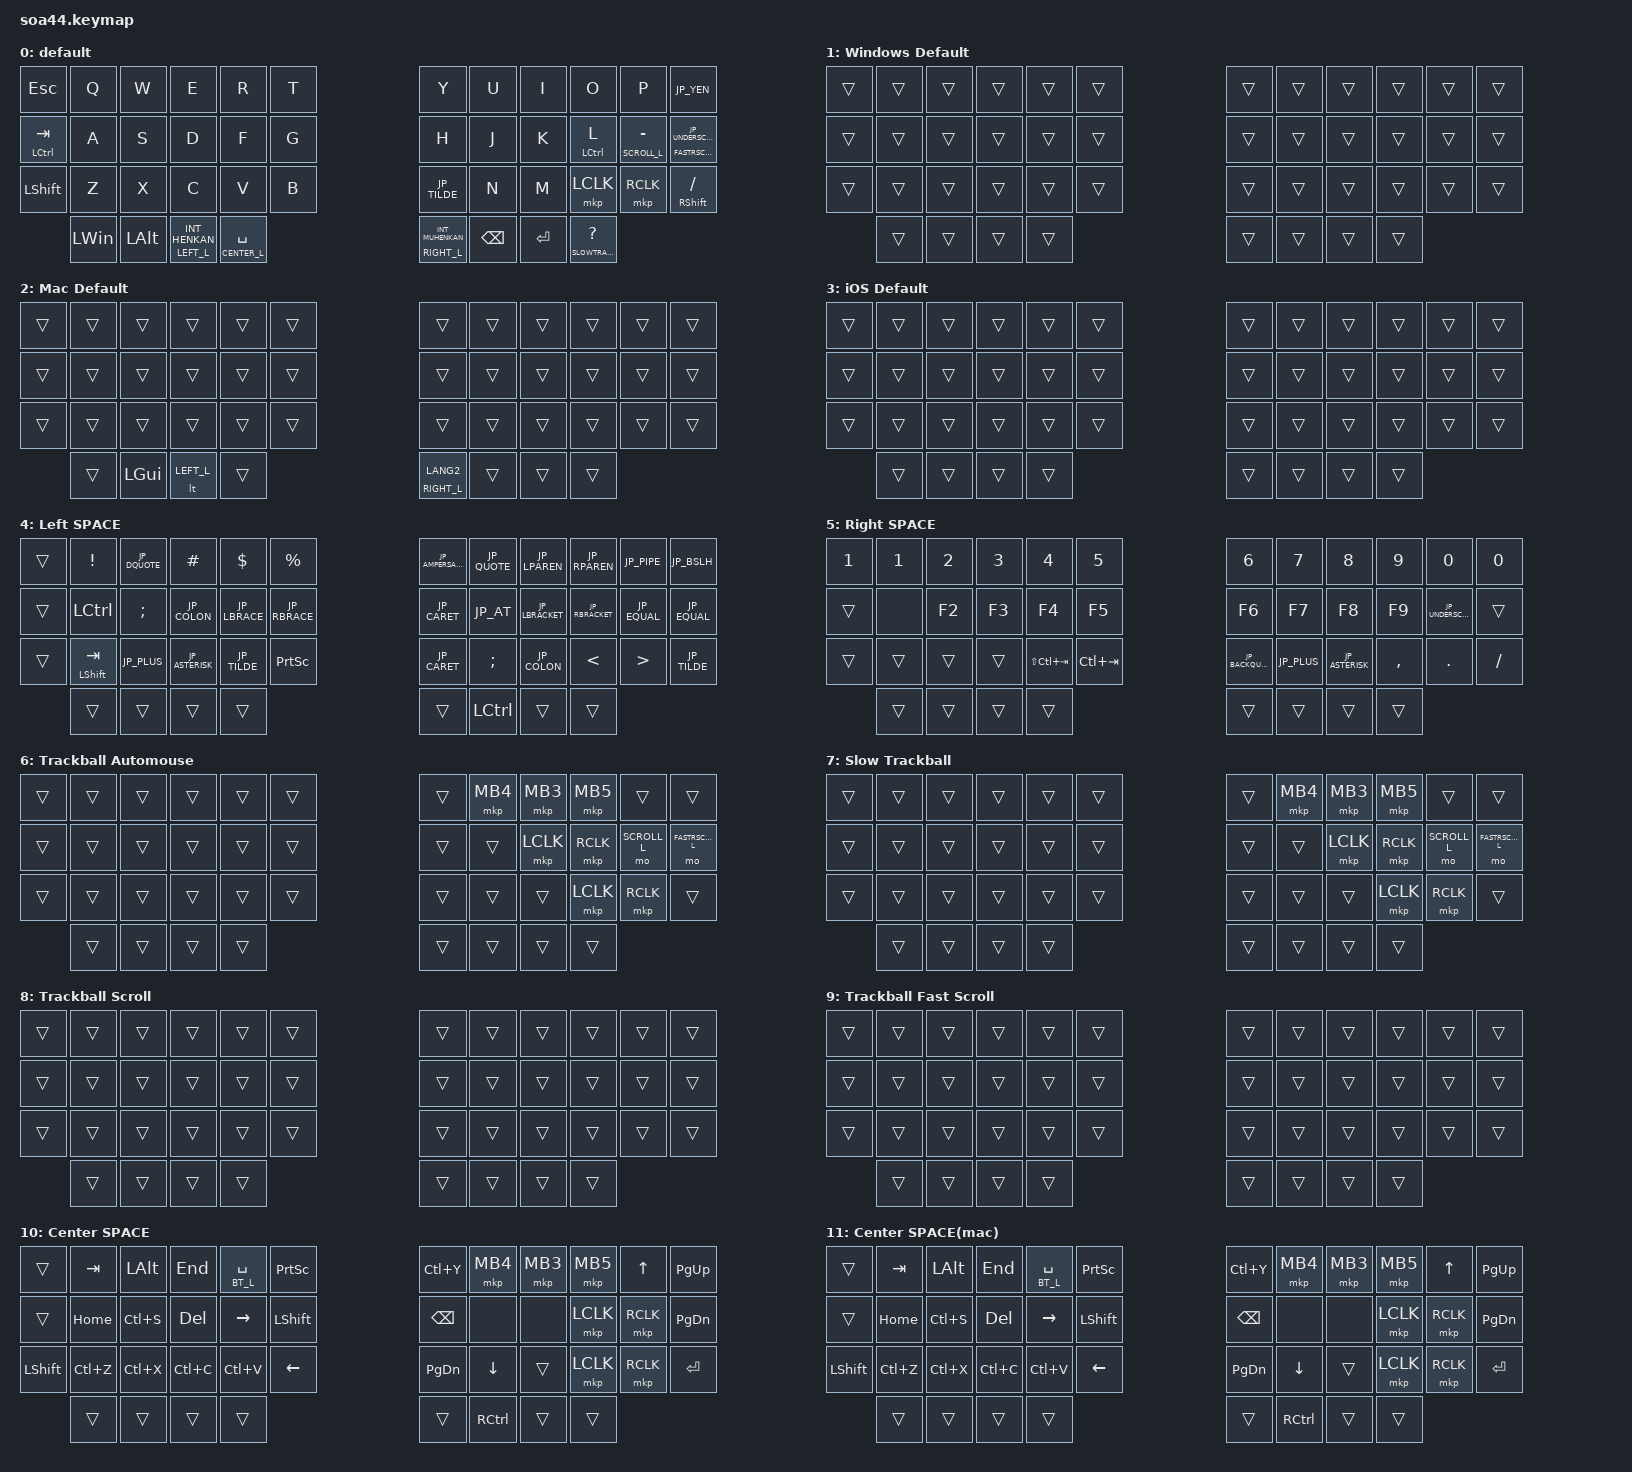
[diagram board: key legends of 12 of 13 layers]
#define JP_DQUOTE       AT                // "
#define JP_AMPERSAND    CARET             // &
#define JP_QUOTE        AMPERSAND         // '
#define JP_EQUAL        UNDER             // =
#define JP_CARET        EQUAL             // ^
#define JP_YEN          0x89              // ¥
#define JP_PLUS         COLON             // +
#define JP_TILDE        PLUS              // ~
#define JP_PIPE         LS(0x89)          // |
#define JP_AT           LEFT_BRACKET      // @
#define JP_COLON        SINGLE_QUOTE      // :
#define JP_ASTERISK     DOUBLE_QUOTES     // *
#define JP_BACKQUOTE    LEFT_BRACE        // `
#define JP_UNDERSCORE   LS(0x87)          // _
#define JP_LBRACKET     RIGHT_BRACKET     // [
#define JP_RBRACKET     BACKSLASH         // ]
#define JP_LPAREN       ASTERISK          // (
#define JP_RPAREN       LEFT_PARENTHESIS  // )
#define JP_LBRACE       RIGHT_BRACE       // {
#define JP_RBRACE       PIPE              // }
#define JP_KANA         LANGUAGE_1        // かな
#define JP_EISU         LANGUAGE_2        // 英数
#define JP_HANZEN       GRAVE             // 半角/全角
#define JP_BSLH         INT1              // (backslash)

// Layer definitions
#include "layers.dtsi"

// ZMK Layout Shift モジュール(https://github.com/kot149/zmk-layout-shift/blob/v1/README_ja.md)を使う
// &kpをオーバーライド

#include <layout_shift_kp_override.dtsi>
#include <behaviors.dtsi>
#include <dt-bindings/zmk/bt.h>
#include <dt-bindings/zmk/keys.h>
#include <dt-bindings/zmk/outputs.h>
#include <dt-bindings/zmk/pointing.h>

&mt {
    flavor = "balanced";
    quick-tap-ms = <0>;
};

/ {
    combos {
        compatible = "zmk,combos";

        tab {
            bindings = <&kp TAB>;
            key-positions = <14 15>;
        };

        shift_tab {
            bindings = <&kp LS(TAB)>;
            key-positions = <15 16>;
        };

        mb4 {
            bindings = <&mkp MB4>;
            key-positions = <7 8>;
        };

        mb5 {
            bindings = <&mkp MB5>;
            key-positions = <8 9>;
        };

        semicolon {
            bindings = <&kp SEMICOLON>;
            key-positions = <19 20>;
        };

        colon {
            bindings = <&kp JP_COLON>;
            key-positions = <20 21>;
        };

        comma {
            bindings = <&kp COMMA>;
            key-positions = <32 33>;
        };

        dot {
            bindings = <&kp DOT>;
            key-positions = <33 34>;
        };

        asterisk {
            bindings = <&kp JP_ASTERISK>;
            key-positions = <32 31>;
        };

        plus {
            bindings = <&kp JP_PLUS>;
            key-positions = <30 31>;
        };

        mb3 {
            bindings = <&mkp MCLK>;
            key-positions = <8 7 9>;
        };

        esc {
            bindings = <&kp ESC>;
            key-positions = <1 2>;
        };
    };

    macros {
        to_layer_0: to_layer_0 {
            compatible = "zmk,behavior-macro-one-param";
            #binding-cells = <1>;
            bindings = <&to 0 &macro_param_1to1 &kp MACRO_PLACEHOLDER>;
            label = "TO_LAYER_0";
        };

        // Disconnect from all once for reliable connection to selected profile.
        // ZMK automatically reconnects to current profile right after disconnection.

        out_bt_nxt: out_bt_nxt {
            compatible = "zmk,behavior-macro";
            #binding-cells = <0>;
            wait-ms = <50>;
            bindings = <&out OUT_BLE &bt BT_NXT &bt BT_DISC 0 &bt BT_DISC 1 &bt BT_DISC 2 &bt BT_DISC 3 &bt BT_DISC 4>;
        };

        // Select specific BT device (0-4) and disconnect others

        out_bt_0: out_bt_0 {
            compatible = "zmk,behavior-macro";
            #binding-cells = <0>;
            wait-ms = <50>;
            bindings = <&out OUT_BLE &bt BT_SEL 0 &bt BT_DISC 1 &bt BT_DISC 2 &bt BT_DISC 3 &bt BT_DISC 4>;
        };

        out_bt_1: out_bt_1 {
            compatible = "zmk,behavior-macro";
            #binding-cells = <0>;
            wait-ms = <50>;
            bindings = <&out OUT_BLE &bt BT_SEL 1 &bt BT_DISC 0 &bt BT_DISC 2 &bt BT_DISC 3 &bt BT_DISC 4>;
        };

        out_bt_2: out_bt_2 {
            compatible = "zmk,behavior-macro";
            #binding-cells = <0>;
            wait-ms = <50>;
            bindings = <&out OUT_BLE &bt BT_SEL 2 &bt BT_DISC 0 &bt BT_DISC 1 &bt BT_DISC 3 &bt BT_DISC 4>;
        };

        out_bt_3: out_bt_3 {
            compatible = "zmk,behavior-macro";
            #binding-cells = <0>;
            wait-ms = <50>;
            bindings = <&out OUT_BLE &bt BT_SEL 3 &bt BT_DISC 0 &bt BT_DISC 1 &bt BT_DISC 2 &bt BT_DISC 4>;
        };

        out_bt_4: out_bt_4 {
            compatible = "zmk,behavior-macro";
            #binding-cells = <0>;
            wait-ms = <50>;
            bindings = <&out OUT_BLE &bt BT_SEL 4 &bt BT_DISC 0 &bt BT_DISC 1 &bt BT_DISC 2 &bt BT_DISC 3>;
        };
    };

    behaviors {
        // for ZMK Layout Shiftモジュール-S
        // KeymapEditor対策で&kpを定義しておく
        // Keep the original key_press behavior for ZMK core components

        original_key_press: original_key_press {
            compatible = "zmk,behavior-key-press";
            #binding-cells = <1>;
            label = "KEY_PRESS";
        };

        // Override the existing &kp behavior to use our custom implementation

        kp: key_press {
            compatible = "zmk,behavior-layout-shift-key-press";
            #binding-cells = <1>;
            label = "LAYOUT_SHIFT_KEY_PRESS";
        };

        // for ZMK Layout Shiftモジュール-ENTER

        lt_to_layer_0: lt_to_layer_0 {
            compatible = "zmk,behavior-hold-tap";
            label = "LAYER_TAP_TO_0";
            bindings = <&mo>, <&to_layer_0>;

            #binding-cells = <2>;
            tapping-term-ms = <200>;
        };
    };

    keymap {
        compatible = "zmk,keymap";

        default {
            bindings = <
&kp ESCAPE      &kp Q         &kp W         &kp E                  &kp R               &kp T                                       &kp Y          &kp U      &kp I      &kp O        &kp P               &kp JP_YEN
&mt LCTRL TAB   &kp A         &kp S         &kp D                  &kp F               &kp G                                       &kp H          &kp J      &kp K      &mt LCTRL L  &lt SCROLL_L MINUS  &lt FASTRSCROLL_L JP_UNDERSCORE
&kp LEFT_SHIFT  &kp Z         &kp X         &kp C                  &kp V               &kp B                        &kp JP_TILDE   &kp N          &kp M      &mkp LCLK  &mkp RCLK    &mt RIGHT_SHIFT SLASH
                &kp LEFT_WIN  &kp LEFT_ALT  &lt LEFT_L INT_HENKAN  &lt CENTER_L SPACE  &lt RIGHT_L INT_MUHENKAN     &kp BACKSPACE  &kp ENTER                            &lt SLOWTRACKBALL_L QUESTION
            >;
        };

        windows_default_layer {
            display-name = "Windows Default";
            bindings = <
&trans  &trans  &trans  &trans  &trans  &trans  &trans  &trans  &trans  &trans  &trans  &trans
&trans  &trans  &trans  &trans  &trans  &trans  &trans  &trans  &trans  &trans  &trans  &trans
&trans  &trans  &trans  &trans  &trans  &trans  &trans  &trans  &trans  &trans  &trans  &trans
        &trans  &trans  &trans  &trans  &trans  &trans  &trans                  &trans
            >;
        };

        mac_default_layer {
            display-name = "Mac Default";
            bindings = <
&trans  &trans  &trans        &trans      &trans  &trans             &trans  &trans  &trans  &trans  &trans  &trans
&trans  &trans  &trans        &trans      &trans  &trans             &trans  &trans  &trans  &trans  &trans  &trans
&trans  &trans  &trans        &trans      &trans  &trans             &trans  &trans  &trans  &trans  &trans  &trans
        &trans  &kp LEFT_GUI  &lt LEFT_L  &trans  &lt RIGHT_L LANG2  &trans  &trans                  &trans
            >;
        };

        ios_default_layer {
            display-name = "iOS Default";
            bindings = <
&trans  &trans  &trans  &trans  &trans  &trans  &trans  &trans  &trans  &trans  &trans  &trans
&trans  &trans  &trans  &trans  &trans  &trans  &trans  &trans  &trans  &trans  &trans  &trans
&trans  &trans  &trans  &trans  &trans  &trans  &trans  &trans  &trans  &trans  &trans  &trans
        &trans  &trans  &trans  &trans  &trans  &trans  &trans                  &trans
            >;
        };

        left_layer {
            display-name = "Left SPACE";

            // --------------------------------------------------------------------------------------------------------------------------------------------------------------------
            // |  ESC    |  !  |  @  |  #       |  $  |  %       |                           |  ^  |  &      |  *      |  (  |  )  |  \  |
            // |         |     |     |          |     |          |                           |  `  |  -      |  =      |  [  |  ]  |SHIFT|
            //           |     |     |          |     |          |                           |     |         |         |     |

            bindings = <
&trans  &kp EXCLAMATION     &kp JP_DQUOTE  &kp HASH         &kp DOLLAR     &kp PERCENT                           &kp JP_AMPERSAND  &kp JP_QUOTE   &kp JP_LPAREN    &kp JP_RPAREN    &kp JP_PIPE       &kp JP_BSLH
&trans  &kp LCTRL           &kp SEMICOLON  &kp JP_COLON     &kp JP_LBRACE  &kp JP_RBRACE                         &kp JP_CARET      &kp JP_AT      &kp JP_LBRACKET  &kp JP_RBRACKET  &kp JP_EQUAL      &kp JP_EQUAL
&trans  &mt LEFT_SHIFT TAB  &kp JP_PLUS    &kp JP_ASTERISK  &kp JP_TILDE   &kp PRINTSCREEN        &kp JP_CARET   &kp SEMICOLON     &kp JP_COLON   &kp LESS_THAN    &kp GREATER_THAN &kp JP_TILDE
        &trans              &trans         &trans           &trans         &trans                 &kp LCTRL      &trans                                            &trans
            >;
        };

        right_layer {
            display-name = "Right SPACE";
            bindings = <
&kp NUMBER_1  &kp NUMBER_1  &kp NUMBER_2  &kp NUMBER_3  &kp NUMBER_4    &kp NUMBER_5                          &kp NUMBER_6  &kp NUMBER_7     &kp NUMBER_8  &kp NUMBER_9  &kp NUMBER_0       &kp N0
&trans        &none         &kp F2        &kp F3        &kp F4          &kp F5                                &kp F6        &kp F7           &kp F8        &kp F9        &kp JP_UNDERSCORE  &trans
&trans        &trans        &trans        &trans        &kp LS(LC(TAB)) &kp LC(TAB)         &kp JP_BACKQUOTE  &kp JP_PLUS   &kp JP_ASTERISK  &kp COMMA     &kp PERIOD    &kp SLASH
              &trans        &trans        &trans        &trans          &trans              &trans            &trans                                       &trans
            >;
        };

        trackball_layer {
            display-name = "Trackball Automouse";
            bindings = <
&trans  &trans  &trans  &trans  &trans  &trans                   &trans  &mkp MB4  &mkp MB3   &mkp MB5   &trans        &trans
&trans  &trans  &trans  &trans  &trans  &trans                   &trans  &trans    &mkp LCLK  &mkp RCLK  &mo SCROLL_L  &mo FASTRSCROLL_L
&trans  &trans  &trans  &trans  &trans  &trans           &trans  &trans  &trans    &mkp LCLK  &mkp RCLK  &trans
        &trans  &trans  &trans  &trans  &trans           &trans  &trans                       &trans
            >;
        };

        slow_trackball_layer {
            display-name = "Slow Trackball";
            bindings = <
&trans  &trans  &trans  &trans  &trans  &trans                   &trans  &mkp MB4  &mkp MB3   &mkp MB5   &trans        &trans
&trans  &trans  &trans  &trans  &trans  &trans                   &trans  &trans    &mkp LCLK  &mkp RCLK  &mo SCROLL_L  &mo FASTRSCROLL_L
&trans  &trans  &trans  &trans  &trans  &trans           &trans  &trans  &trans    &mkp LCLK  &mkp RCLK  &trans
        &trans  &trans  &trans  &trans  &trans           &trans  &trans                       &trans
            >;
        };


        scroll_layer {
            display-name = "Trackball Scroll";
            bindings = <
&trans  &trans  &trans  &trans  &trans  &trans  &trans  &trans  &trans  &trans  &trans  &trans
&trans  &trans  &trans  &trans  &trans  &trans  &trans  &trans  &trans  &trans  &trans  &trans
&trans  &trans  &trans  &trans  &trans  &trans  &trans  &trans  &trans  &trans  &trans  &trans
        &trans  &trans  &trans  &trans  &trans  &trans  &trans                  &trans
            >;
        };

        fast_scroll_layer {
            display-name = "Trackball Fast Scroll";
            bindings = <
&trans  &trans  &trans  &trans  &trans  &trans  &trans  &trans  &trans  &trans  &trans  &trans
&trans  &trans  &trans  &trans  &trans  &trans  &trans  &trans  &trans  &trans  &trans  &trans
&trans  &trans  &trans  &trans  &trans  &trans  &trans  &trans  &trans  &trans  &trans  &trans
        &trans  &trans  &trans  &trans  &trans  &trans  &trans                  &trans
            >;
        };


        center_layer {
            display-name = "Center SPACE";
            bindings = <
&trans          &kp TAB    &kp LEFT_ALT  &kp END    &lt BT_L SPACE   &kp PRINTSCREEN                       &kp LC(Y)      &mkp MB4  &mkp MB3  &mkp MB5   &kp UP_ARROW  &kp PAGE_UP
&trans          &kp HOME   &kp LC(S)     &kp DEL    &kp RIGHT_ARROW  &kp LEFT_SHIFT                        &kp BACKSPACE  &none     &none     &mkp LCLK  &mkp RCLK     &kp PAGE_DOWN
&kp LEFT_SHIFT  &kp LC(Z)  &kp LC(X)     &kp LC(C)  &kp LC(V)        &kp LEFT_ARROW         &kp PAGE_DOWN  &kp DOWN_ARROW &trans    &mkp LCLK &mkp RCLK  &kp ENTER
                &trans     &trans        &trans     &trans           &trans                 &kp RCTRL      &trans                             &trans
            >;
        };

        center2_layer {
            display-name = "Center SPACE(mac)";
            bindings = <
&trans          &kp TAB    &kp LEFT_ALT  &kp END    &lt BT_L SPACE   &kp PRINTSCREEN                       &kp LC(Y)      &mkp MB4  &mkp MB3  &mkp MB5   &kp UP_ARROW  &kp PAGE_UP
&trans          &kp HOME   &kp LC(S)     &kp DEL    &kp RIGHT_ARROW  &kp LEFT_SHIFT                        &kp BACKSPACE  &none     &none     &mkp LCLK  &mkp RCLK     &kp PAGE_DOWN
&kp LEFT_SHIFT  &kp LC(Z)  &kp LC(X)     &kp LC(C)  &kp LC(V)        &kp LEFT_ARROW         &kp PAGE_DOWN  &kp DOWN_ARROW &trans    &mkp LCLK &mkp RCLK  &kp ENTER
                &trans     &trans        &trans     &trans           &trans                 &kp RCTRL      &trans                             &trans
            >;
        };

        Bluetooth {
            bindings = <
&trans  &trans  &trans  &trans  &trans  &trans                               &out_bt_0  &out_bt_1  &out_bt_2  &out_bt_3  &out_bt_4  &trans
&trans  &trans  &trans  &trans  &trans  &trans                               &trans     &trans     &trans     &trans     &trans     &trans
&trans  &trans  &trans  &trans  &trans  &trans           &kp RC(RA(DELETE))  &trans     &trans     &trans     &trans     &bt BT_CLR
        &trans  &trans  &trans  &trans  &trans           &bootloader         &trans                           &bt BT_CLR_ALL
            >;
        };
    };
};
